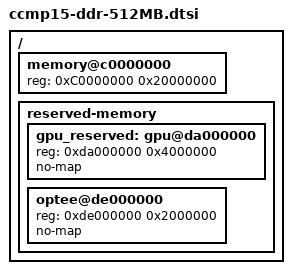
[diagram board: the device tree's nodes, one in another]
// SPDX-License-Identifier: (GPL-2.0+ OR BSD-3-Clause)
/*
 * Copyright (C) 2023,2024 Digi International Inc - All Rights Reserved
 */

/ {
	memory@c0000000 {
		device_type = "memory";
		reg = <0xC0000000 0x20000000>; /* 512 MiB */
	};

	reserved-memory {
		gpu_reserved: gpu@da000000 {
			reg = <0xda000000 0x4000000>;
			no-map;
		};

		/* Reserve the upper 32 MiB */
		optee@de000000 {
			reg = <0xde000000 0x2000000>;
			no-map;
		};
	};
};
